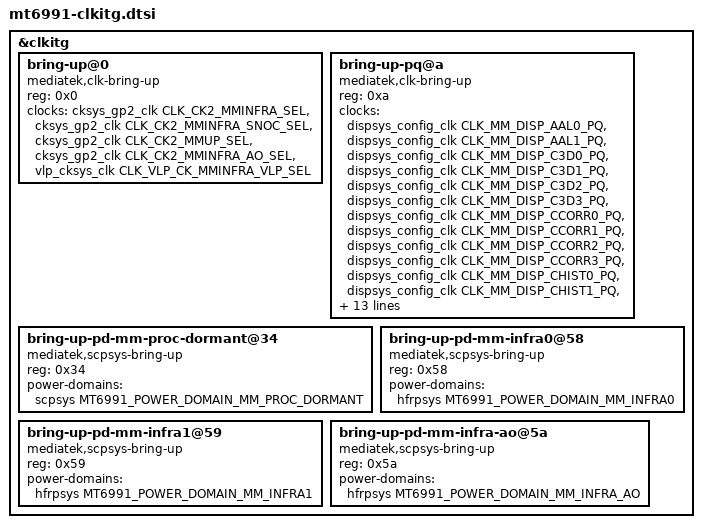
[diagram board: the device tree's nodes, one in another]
// SPDX-License-Identifier: (GPL-2.0 OR MIT)
/*
 * Copyright (C) 2023 MediaTek Inc.
 * Author: Chong-ming Wei <chong-ming.wei@mediatek.com>
 */

&clkitg {
	status = "okay";
	bring-up@0 {
		compatible = "mediatek,clk-bring-up";
		reg = <0x0>;
		clocks =
			<&cksys_gp2_clk CLK_CK2_MMINFRA_SEL>,
			<&cksys_gp2_clk CLK_CK2_MMINFRA_SNOC_SEL>,
			<&cksys_gp2_clk CLK_CK2_MMUP_SEL>,
			<&cksys_gp2_clk CLK_CK2_MMINFRA_AO_SEL>,
			<&vlp_cksys_clk CLK_VLP_CK_MMINFRA_VLP_SEL>;
	};
	bring-up-pq@a {
		compatible = "mediatek,clk-bring-up";
		reg = <0xa>;
		clocks =
			<&dispsys_config_clk CLK_MM_DISP_AAL0_PQ>,
			<&dispsys_config_clk CLK_MM_DISP_AAL1_PQ>,
			<&dispsys_config_clk CLK_MM_DISP_C3D0_PQ>,
			<&dispsys_config_clk CLK_MM_DISP_C3D1_PQ>,
			<&dispsys_config_clk CLK_MM_DISP_C3D2_PQ>,
			<&dispsys_config_clk CLK_MM_DISP_C3D3_PQ>,
			<&dispsys_config_clk CLK_MM_DISP_CCORR0_PQ>,
			<&dispsys_config_clk CLK_MM_DISP_CCORR1_PQ>,
			<&dispsys_config_clk CLK_MM_DISP_CCORR2_PQ>,
			<&dispsys_config_clk CLK_MM_DISP_CCORR3_PQ>,
			<&dispsys_config_clk CLK_MM_DISP_CHIST0_PQ>,
			<&dispsys_config_clk CLK_MM_DISP_CHIST1_PQ>,
			<&dispsys_config_clk CLK_MM_DISP_COLOR0_PQ>,
			<&dispsys_config_clk CLK_MM_DISP_COLOR1_PQ>,
			<&dispsys_config_clk CLK_MM_DISP_DITHER0_PQ>,
			<&dispsys_config_clk CLK_MM_DISP_DITHER1_PQ>,
			<&dispsys_config_clk CLK_MM_DISP_GAMMA0_PQ>,
			<&dispsys_config_clk CLK_MM_DISP_GAMMA1_PQ>,
			<&dispsys_config_clk CLK_MM_MDP_AAL0_PQ>,
			<&dispsys_config_clk CLK_MM_MDP_AAL1_PQ>,
			<&dispsys_config_clk CLK_MM_DISP_TDSHP0_PQ>,
			<&dispsys_config_clk CLK_MM_DISP_TDSHP1_PQ>,
			<&dispsys1_config_clk CLK_MM1_DISP_ODDMR0_PQ>,
			<&dispsys1_config_clk CLK_MM1_DISP_POSTALIGN0_PQ>,
			<&dispsys1_config_clk CLK_MM1_DISP_DITHER2_PQ>;
	};
	bring-up-pd-mm-proc-dormant@34 {
		compatible = "mediatek,scpsys-bring-up";
		reg = <0x34>;
		power-domains = <&scpsys MT6991_POWER_DOMAIN_MM_PROC_DORMANT>;
	};
	bring-up-pd-mm-infra0@58 {
		compatible = "mediatek,scpsys-bring-up";
		reg = <0x58>;
		power-domains = <&hfrpsys MT6991_POWER_DOMAIN_MM_INFRA0>;
	};
	bring-up-pd-mm-infra1@59 {
		compatible = "mediatek,scpsys-bring-up";
		reg = <0x59>;
		power-domains = <&hfrpsys MT6991_POWER_DOMAIN_MM_INFRA1>;
	};
	bring-up-pd-mm-infra-ao@5a {
		compatible = "mediatek,scpsys-bring-up";
		reg = <0x5a>;
		power-domains = <&hfrpsys MT6991_POWER_DOMAIN_MM_INFRA_AO>;
	};
};
